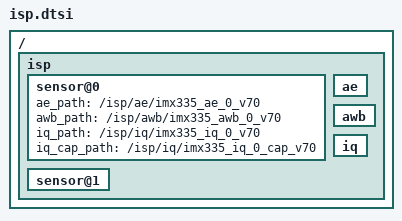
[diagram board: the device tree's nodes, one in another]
/ {
	isp {
		sensor@0 {
			ae_path                 = "/isp/ae/imx335_ae_0_v70";
			awb_path                = "/isp/awb/imx335_awb_0_v70";
			iq_path                 = "/isp/iq/imx335_iq_0_v70";
			iq_cap_path				= "/isp/iq/imx335_iq_0_cap_v70";
		};
		sensor@1 {
		};
		/* label for ae, awb, iq table */
		ae: ae {
		};
		awb: awb {
		};
		iq: iq {
		};
	};
};

/* Note: put include files in the tail since label should be declared first. */
#include "imx415_ae_0_v70.dtsi"
#include "imx415_awb_0_v70.dtsi"
#include "imx415_iq_0_v70.dtsi"
#include "imx415_iq_0_cap_v70.dtsi"

